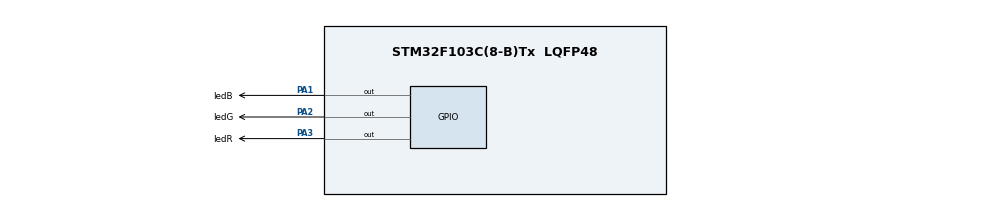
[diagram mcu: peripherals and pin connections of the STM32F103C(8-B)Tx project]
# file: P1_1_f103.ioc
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Mcu.Family=STM32F1
Mcu.Name=STM32F103C(8-B)Tx
Mcu.Package=LQFP48
NVIC.PriorityGroup=NVIC_PRIORITYGROUP_4
PA1.GPIO_Label=ledB
PA1.GPIO_ModeDefaultOutputPP=GPIO_MODE_OUTPUT_OD
PA1.GPIO_PuPd=GPIO_NOPULL
PA1.Signal=GPIO_Output
PA13.Mode=Serial_Wire
PA13.Signal=SYS_JTMS-SWDIO
PA14.Mode=Serial_Wire
PA14.Signal=SYS_JTCK-SWCLK
PA2.GPIO_Label=ledG
PA2.GPIO_ModeDefaultOutputPP=GPIO_MODE_OUTPUT_OD
PA2.GPIO_PuPd=GPIO_NOPULL
PA2.Signal=GPIO_Output
PA3.GPIO_Label=ledR
PA3.GPIO_ModeDefaultOutputPP=GPIO_MODE_OUTPUT_OD
PA3.GPIO_PuPd=GPIO_NOPULL
PA3.Signal=GPIO_Output
ProjectManager.HeapSize=0x200
ProjectManager.StackSize=0x400
ProjectManager.TargetToolchain=STM32CubeIDE
RCC.APB1Freq_Value=8000000
RCC.APB2Freq_Value=8000000
board=custom

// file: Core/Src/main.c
/* USER CODE BEGIN Header */
/**
  ******************************************************************************
  * @file           : main.c
  * @brief          : Main program body
  ******************************************************************************
  * @attention
  *
  * Copyright (c) 2023 STMicroelectronics.
  * All rights reserved.
  *
  * This software is licensed under terms that can be found in the LICENSE file
  * in the root directory of this software component.
  * If no LICENSE file comes with this software, it is provided AS-IS.
  *
  ******************************************************************************
  */
/* USER CODE END Header */
#include "main.h"

/* USER CODE BEGIN PV */

typedef struct {
	uint16_t pin;
	GPIO_TypeDef* port;
} led_typedef; 				//estructura para guardar el pin y el puerto de cada led

/*
 * los pines de led están definidos en CubeMx:
 * ledB --> PIN A1
 * ledG --> PIN A2
 * ledR --> PIN A3
 */

led_typedef ledRed = {ledR_Pin, ledR_GPIO_Port};
led_typedef ledGreen = {ledG_Pin, ledG_GPIO_Port};
led_typedef ledBlue = {ledB_Pin, ledB_GPIO_Port};

led_typedef *ledArray[] = {&ledRed, &ledGreen, &ledBlue}; //la secuencia de encendido de leds

const uint8_t NUM_LEDS = 3;
const uint8_t ON_TIME_MS = 200;
/* USER CODE END PV */

void SystemClock_Config(void);
static void MX_GPIO_Init(void);
/* USER CODE BEGIN PFP */

//funciones que uso para encender o apagar uno o todos los leds
void led_on(led_typedef*);
void led_off(led_typedef*);
void led_off_all(led_typedef*[]);

/* USER CODE END PFP */

int main(void)
{

  /* MCU Configuration--------------------------------------------------------*/

  /* Reset of all peripherals, Initializes the Flash interface and the Systick. */
  HAL_Init();

  /* Configure the system clock */
  SystemClock_Config();

  /* Initialize all configured peripherals */
  MX_GPIO_Init();

  /* Infinite loop */
  /* USER CODE BEGIN WHILE */

  led_off_all(ledArray);
  while (1)
  {
    /* USER CODE END WHILE */

    /* USER CODE BEGIN 3 */
	  for(int i=0; i<NUM_LEDS; i++){
		  led_on(ledArray[i]);
		  HAL_Delay(ON_TIME_MS);
		  led_off_all(ledArray);
		  HAL_Delay(ON_TIME_MS);
	  }
  }
  /* USER CODE END 3 */
}

void SystemClock_Config(void)
{
  RCC_OscInitTypeDef RCC_OscInitStruct = {0};
  RCC_ClkInitTypeDef RCC_ClkInitStruct = {0};

  /** Initializes the RCC Oscillators according to the specified parameters
  * in the RCC_OscInitTypeDef structure.
  */
  RCC_OscInitStruct.OscillatorType = RCC_OSCILLATORTYPE_HSI;
  RCC_OscInitStruct.HSIState = RCC_HSI_ON;
  RCC_OscInitStruct.HSICalibrationValue = RCC_HSICALIBRATION_DEFAULT;
  RCC_OscInitStruct.PLL.PLLState = RCC_PLL_NONE;
  if (HAL_RCC_OscConfig(&RCC_OscInitStruct) != HAL_OK)
  {
    Error_Handler();
  }

  /** Initializes the CPU, AHB and APB buses clocks
  */
  RCC_ClkInitStruct.ClockType = RCC_CLOCKTYPE_HCLK|RCC_CLOCKTYPE_SYSCLK
                              |RCC_CLOCKTYPE_PCLK1|RCC_CLOCKTYPE_PCLK2;
  RCC_ClkInitStruct.SYSCLKSource = RCC_SYSCLKSOURCE_HSI;
  RCC_ClkInitStruct.AHBCLKDivider = RCC_SYSCLK_DIV1;
  RCC_ClkInitStruct.APB1CLKDivider = RCC_HCLK_DIV1;
  RCC_ClkInitStruct.APB2CLKDivider = RCC_HCLK_DIV1;

  if (HAL_RCC_ClockConfig(&RCC_ClkInitStruct, FLASH_LATENCY_0) != HAL_OK)
  {
    Error_Handler();
  }
}

static void MX_GPIO_Init(void)
{
  GPIO_InitTypeDef GPIO_InitStruct = {0};

  /* GPIO Ports Clock Enable */
  __HAL_RCC_GPIOA_CLK_ENABLE();

  /*Configure GPIO pin Output Level */
  HAL_GPIO_WritePin(GPIOA, ledB_Pin|ledG_Pin|ledR_Pin, GPIO_PIN_RESET);

  /*Configure GPIO pins : ledB_Pin ledG_Pin ledR_Pin */
  GPIO_InitStruct.Pin = ledB_Pin|ledG_Pin|ledR_Pin;
  GPIO_InitStruct.Mode = GPIO_MODE_OUTPUT_OD;
  GPIO_InitStruct.Pull = GPIO_NOPULL;
  GPIO_InitStruct.Speed = GPIO_SPEED_FREQ_LOW;
  HAL_GPIO_Init(GPIOA, &GPIO_InitStruct);

}

/* USER CODE BEGIN 4 */

/* los leds están conectados a los pines de la placa en la configuración open-drain.
 * Por lo tanto para encender un led, el estado del pin debe ser 0 (GPIO_PIN_RESET),
 * y para apagarlo el estado debe ser 1 (GPIO_PIN_SET).
 * */

void led_on(led_typedef *led){
	HAL_GPIO_WritePin(led->port, led->pin, GPIO_PIN_RESET);
}

void led_off(led_typedef *led){
	HAL_GPIO_WritePin(led->port, led->pin, GPIO_PIN_SET);
}

void led_off_all(led_typedef *leds[]){
	for(int i=0; i<NUM_LEDS; i++){
		led_off(leds[i]);
	}
}
/* USER CODE END 4 */

void Error_Handler(void)
{
  __disable_irq();
  while (1)
  {
  }
}
